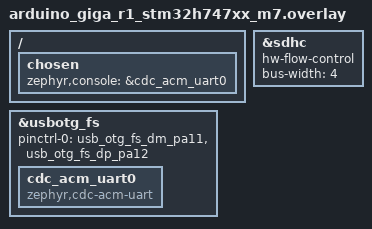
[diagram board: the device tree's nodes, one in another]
/*
 * Copyright (c) 2025 EXALT Technologies.
 *
 * SPDX-License-Identifier: Apache-2.0
 */

/ {
	chosen {
		zephyr,console = &cdc_acm_uart0;
	};
};

&usbotg_fs {
	status = "okay";
	pinctrl-0 = <&usb_otg_fs_dm_pa11 &usb_otg_fs_dp_pa12>;
	pinctrl-names = "default";

	cdc_acm_uart0: cdc_acm_uart0 {
		status = "okay";
		compatible = "zephyr,cdc-acm-uart";
	};
};

&cdc_acm_uart0 {
	status = "okay";
};

&sdhc {
	hw-flow-control;
	bus-width = <4>;
};
